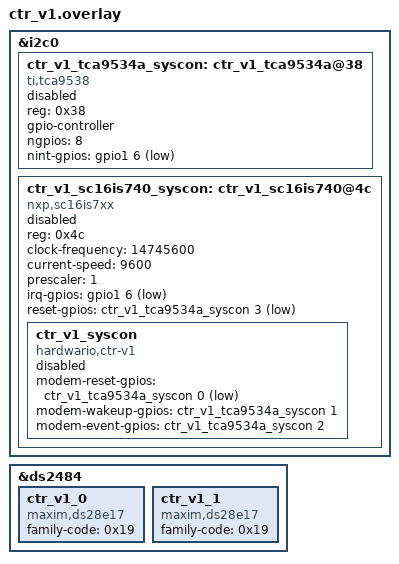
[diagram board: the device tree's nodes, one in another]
&i2c0 {
	ctr_v1_tca9534a_syscon: ctr_v1_tca9534a@38 {
		compatible = "ti,tca9538";
		status = "disabled";
		reg = <0x38>;
		#gpio-cells = <2>;
		gpio-controller;
		ngpios = <8>;
		nint-gpios = <&gpio1 6 GPIO_ACTIVE_LOW>;
	};

	ctr_v1_sc16is740_syscon: ctr_v1_sc16is740@4c {
		compatible = "nxp,sc16is7xx";
		status = "disabled";
		reg = <0x4c>;
		clock-frequency = <14745600>;
		current-speed = <9600>;
		prescaler = <1>;
		irq-gpios = <&gpio1 6 GPIO_ACTIVE_LOW>;
		reset-gpios = <&ctr_v1_tca9534a_syscon 3 GPIO_ACTIVE_LOW>;

		ctr_v1_syscon: ctr_v1_syscon {
			compatible = "hardwario,ctr-v1";
			status = "disabled";
			modem-reset-gpios = <&ctr_v1_tca9534a_syscon 0 GPIO_ACTIVE_LOW>;
			modem-wakeup-gpios = <&ctr_v1_tca9534a_syscon 1 GPIO_ACTIVE_HIGH>;
			modem-event-gpios = <&ctr_v1_tca9534a_syscon 2 GPIO_ACTIVE_HIGH>;
		};
	};
};

&ds2484 {
	ctr_v1_0: ctr_v1_0 {
		compatible = "maxim,ds28e17";
		family-code = <0x19>;
	};
	ctr_v1_1: ctr_v1_1 {
		compatible = "maxim,ds28e17";
		family-code = <0x19>;
	};
};
